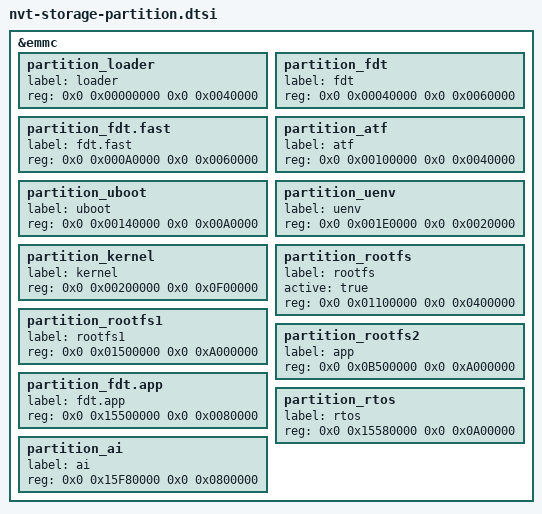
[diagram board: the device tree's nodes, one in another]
/*
 * Novatek Ltd. BSP part of dts
 */

&emmc {
	partition_loader {      label = "loader";                      reg = <0x0 0x00000000 0x0 0x0040000>; }; /* Fixed */
	partition_fdt {         label = "fdt";                         reg = <0x0 0x00040000 0x0 0x0060000>; }; /* Fixed */
	partition_fdt.fast {    label = "fdt.fast";                    reg = <0x0 0x000A0000 0x0 0x0060000>; }; /* Fixed */
	partition_atf {         label = "atf";                         reg = <0x0 0x00100000 0x0 0x0040000>; };
	partition_uboot {       label = "uboot";                       reg = <0x0 0x00140000 0x0 0x00A0000>; };
	partition_uenv {        label = "uenv";                        reg = <0x0 0x001E0000 0x0 0x0020000>; };
	partition_kernel {      label = "kernel";                      reg = <0x0 0x00200000 0x0 0x0F00000>; };
	partition_rootfs {      label = "rootfs";  active="true";      reg = <0x0 0x01100000 0x0 0x0400000>; };
	partition_rootfs1 {     label = "rootfs1";                     reg = <0x0 0x01500000 0x0 0xA000000>; };
	partition_rootfs2 {     label = "app";                         reg = <0x0 0x0B500000 0x0 0xA000000>; };
	partition_fdt.app {     label = "fdt.app";                     reg = <0x0 0x15500000 0x0 0x0080000>; };
	partition_rtos {        label = "rtos";                        reg = <0x0 0x15580000 0x0 0x0A00000>; };
	partition_ai {          label = "ai";                          reg = <0x0 0x15F80000 0x0 0x0800000>; };
};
